# a34g43x register map
Vendor: ABOV Semiconductor Co., Ltd.; File version: 1.0
CPU: CM4 r0p1, little endian, MPU, FPU, VTOR, 4 interrupt priority bits
Registers are 32-bit, read-write, reset 0x0 unless marked. A register's access mark holds for its fields unless they carry their own. Offsets are from the block's base; [hi:lo] are bit positions; 'fields as' and 'values as' point back to an identical list.

## QSPI — Serial Peripheral Interface Bus
Base 0x40020000
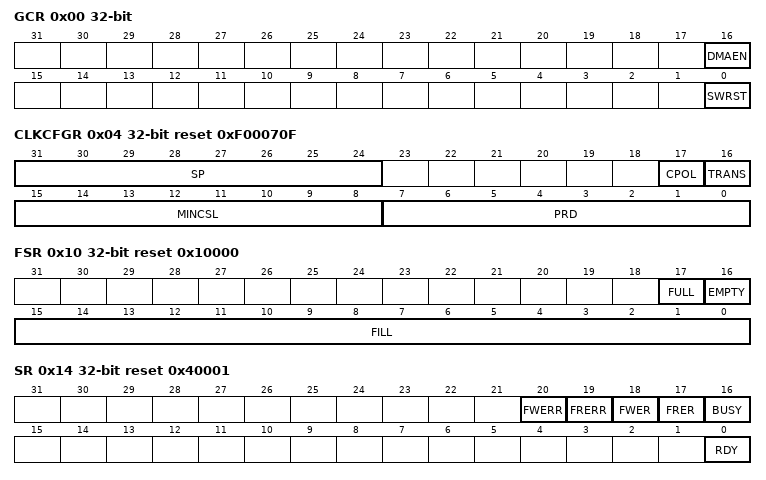
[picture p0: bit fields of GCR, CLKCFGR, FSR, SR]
0x00 GCR — QSPI Global Control Register
  [16] DMAEN — To complete next command using DMA, set this bit to 1.
  [0] SWRST — When set '1', holds most of the internal logic in reset
0x04 CLKCFGR reset 0xF00070F — QSPI Clock Configuration Register
  [31:24] SP — Sets the sampling point of the input
  [17] CPOL — Selects the clock polarity as follows
    0=Start_Low (QSPI clock output starts low and ends low); 1=Start_High (QSPI clock output starts high and ends high)
  [16] TRANS — Select the clock edge on which the output data is changed
  [15:8] MINCSL — Time between CS going active and first clock edge
  [7:0] PRD — The period of the QSPI output clock
0x08 MINCSHR — QSPI Minimum Chip Select High Register
  [7:0] MINCSHR — Required to drive the CS line inactive.
0x10 FSR ro reset 0x10000 — QSPI FIFO Status Register
  [17] FULL — The QSPI FIFO full status bit
    0=NOT_FULL (FIFO is not full); 1=FULL (FIFO is full)
  [16] EMPTY — The QSPI FIFO empty status bit
    0=NOT_EMPTY (FIFO is not empty); 1=EMPTY (FIFO is empty)
  [15:0] FILL — Current FIFO fill level
0x14 SR reset 0x40001 — QSPI Status Register
  [20] FWERR — Erroneous (unexpected) FIFO write detected flag.
  [19] FRERR — Erroneous (unexpected) FIFO read detected.
  [18] FWER ro — Write FIFO indicate status bit.
  [17] FRER ro — Read FIFO indicate status bit.
  [16] BUSY ro — QSPI busy status bit
  [0] RDY ro — QSPI idle status bit.
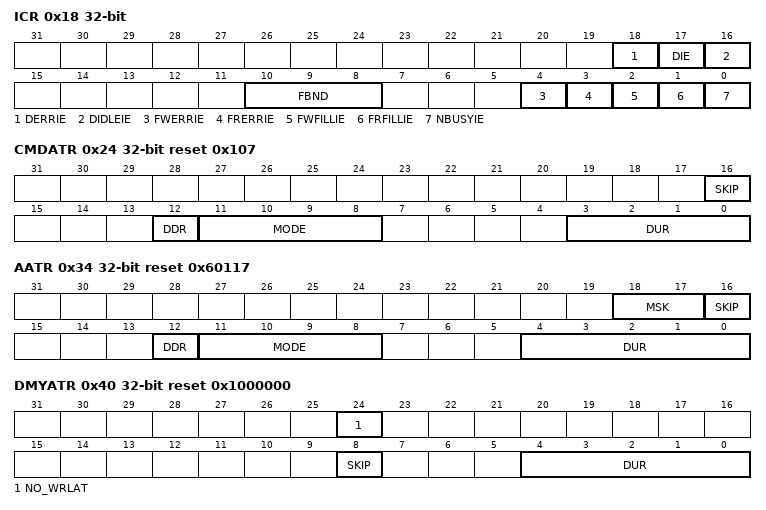
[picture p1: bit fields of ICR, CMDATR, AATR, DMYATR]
0x18 ICR — QSPI Interrupt Control Register
  [18] DERRIE — DMA error interrupt bit.
  [17] DIE — DMA interrupt bit.
  [16] DIDLEIE — DMA idle interrupt bit.
  [10:8] FBND — FIFO boundary
  [4] FWERRIE — Write FIFO error interrupt bit.
  [3] FRERRIE — Read FIFO error interrupt bit.
  [2] FWFILLIE — Write FIFO fill interrupt bit.
  [1] FRFILLIE — Read FIFO fill interrupt bit.
  [0] NBUSYIE — Not busy interrupt bit.
0x20 CMDR — QSPI Command Register
  [15:0] CMD — For commands less than 16 bits wide, align command's most significant bit to bit [15]
0x24 CMDATR reset 0x107 — QSPI Command Atrributes Register
  [16] SKIP — This bit selects whether the command phase is to be skipped or not on the next QSPI transaction and is encoded as follows
  [12] DDR — This bit selects whether the command phase is executed in DDR mode (using both edges of the output clock)
  [11:8] MODE — This field selects the number of lines to use for the command output
    1=Single (x1, 1-bits); 2=Dual (x2, 2-bits); 4=Quad (x4, 4-bits)
  [3:0] DUR — This field must reflect the length of the command phase of the QSPI transaction in QSPI clock cycles minus 1
0x30 AR — QSPI Address Register
  [31:0] ADDR — This field holds the value of the address output on the address phase of the QSPI transaction
0x34 AATR reset 0x60117 — QSPI Address Atrributes Register
  [18:17] MSK — Always '3'.
  [16] SKIP — This bit selects whether the address phase is to be skipped or not on the next QSPI transaction
  [12] DDR — This bit selects whether the address phase is executed in DDR mode (using both edges of the output clock)
  [11:8] MODE — This field selects the number of lines to use for the address output
    values as CMDATR.MODE
  [4:0] DUR — This field must reflect the length of the address phase of the QSPI transaction in QSPI clock cycles minus 1
0x38 CSR reset 0x1 — QSPI Chip Select Register
  [0] CS — Chip Select line.
0x40 DMYATR reset 0x1000000 — QSPI Dummy Attributes Register
  [24] NO_WRLAT — Always '1'.
  [8] SKIP — This bit selects whether the dummy phase is to be skipped or not on the next QSPI transaction
  [4:0] DUR — This field reflects the length of the dummy phase of the SPI transaction in QSPI clock cycles minus 1
0x44 XIPHOTR — QSPI XIP Hold Off Time Register
  [31:0] TIME — when the command is executed with bit [31]='1' in the QSPI Command Attributes Register.
0x48 XIPHOSR — QSPI XIP Hold Off Select Register
  [0] EN — This register gives the XIP windows for which the XIP hold off should be applied
0x4C XIPHOCR — QSPI XIP Hold Off Control Register
  [0] EN — Hold off in XIP enable bit.
0x50 DSZR — QSPI Data Size Register
  [31:0] SIZE — Number of data bits to transmit or receive, minus 1.
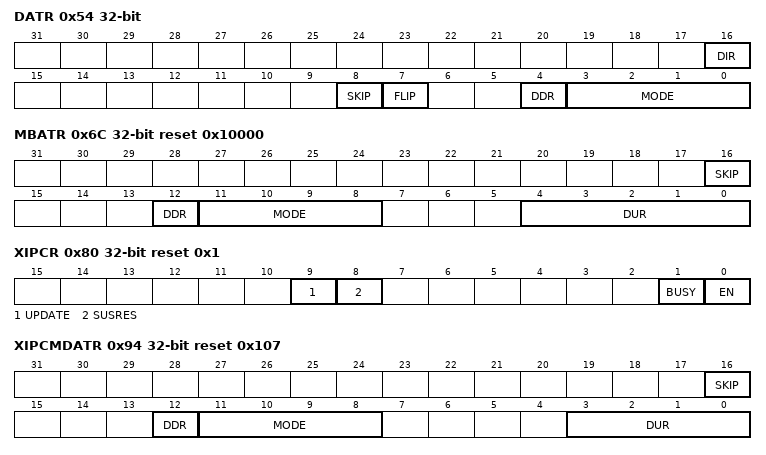
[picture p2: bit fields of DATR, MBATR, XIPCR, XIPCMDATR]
0x54 DATR — QSPI Data Attributes Register
  [16] DIR — Data direction select
  [8] SKIP — This bit selects whether the data phase is to be skipped or not on the next QSPI transaction
  [7] FLIP — Byte order select
  [4] DDR — This bit selects whether the data phase is executed in DDR mode (using both edges of the clock)
  [3:0] MODE — This field selects the number of lines to use for the data output
    values as CMDATR.MODE
0x58 TDR wo — QSPI Transmit Data Register
  [31:0] TDR — Window into the QSPI custom command data FIFO. Writing this register pushes one 32-bit word into the QSPI custom command data FIFO.
0x5C RDR ro — QSPI Receive Data Register
  [31:0] RDR — Window into the SPI custom command data FIFO. Reading this register pops one 32-bit word from the QSPI custom command data FIFO.
0x68 MBR — QSPI Mode Bits Register
  [31:0] MODE — QSPI Mode bits to use for the mode phase of the QSPI transaction
0x6C MBATR reset 0x10000 — QSPI Mode Bits Attributes Register
  [16] SKIP — This bit selects whether the mode phase is to be skipped or not on the next
  [12] DDR — This bit selects whether the mode phase is executed in DDR mode (using both edges of the clock)
  [11:8] MODE — This field selects the number of lines to use for the mode output
    values as CMDATR.MODE
  [4:0] DUR — This field must reflect the length of the mode phase of the QSPI transaction in QSPI clock cycles minus 1
0x80 XIPCR reset 0x1 — XIP Control Register
  [9] UPDATE — If this bit is set to 1, the attributes specified in the New XIP * registers are applied
  [8] SUSRES — Set to 1 to enable suspend/resume support. Setting this bit is only applied when bit [9] is also set to 1
  [1] BUSY — XIP operation state
  [0] EN — Enable the XIP window.
0x84 XIPACCBNDR reset 0x1F — QSPI XIP Access Boundary Register
  [4:0] BND — Access boundary for XIP accesses
0x88 XIPSZR reset 0x1FFFFF — QSPI XIP Size Register
  [27:0] SIZE — This register gives the size of this XIP window
0x8C XIPWINAR — QSPI XIP Window Address Register
  [27:0] ADDR — For window 0: This register is hard wired to '0'
0x90 XIPCMDR reset 0xB00 — QSPI XIP Command Register
  [15:0] RCMD — QSPI command to use for XIP reads.
0x94 XIPCMDATR reset 0x107 — QSPI XIP Command Attributes Register
  [16] SKIP — This bit selects whether the command phase is to be skipped or not for XIP-based QSPI transactions
  [12] DDR — This bit selects whether the command phase is executed in DDR mode (using both edges of the output clock)
  [11:8] MODE — This field selects the number of lines to use for XIP command output
    values as CMDATR.MODE
  [3:0] DUR — This field must reflect the length of the command phase of the XIP read in QSPI clock cycles minus 1
0xA0 XIPBAR — QSPI XIP Base Address Register
  [31:0] ADDR — This register selects the memory address to which the controller maps address 0 on the XIP slave interface.
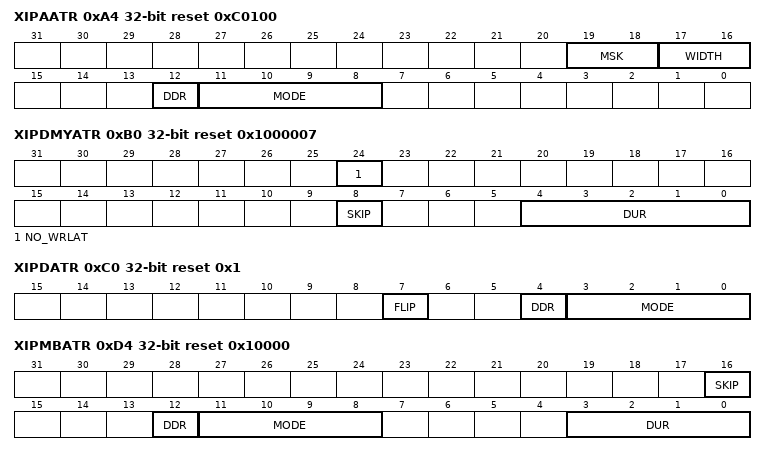
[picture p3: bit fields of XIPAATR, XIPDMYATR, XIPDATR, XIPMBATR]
0xA4 XIPAATR reset 0xC0100 — QSPI XIP Address Attributes Register
  [19:18] MSK — Always '3'.
  [17:16] WIDTH — Select address length used for XIP reads
  [12] DDR — Address DDR mode after update
  [11:8] MODE — This field selects the number of lines to use for the address output
    values as CMDATR.MODE
0xA8 XIPCSR reset 0x1 — QSPI XIP Chip Select Register
  [0] CS — The chip select line to use for XIP mode reads
0xB0 XIPDMYATR reset 0x1000007 — QSPI XIP Dummy Attributes Register
  [24] NO_WRLAT — Always '1'.
  [8] SKIP — This bit selects whether the dummy phase is to be skipped or not on XIP reads
  [4:0] DUR — This field reflects the length of the dummy phase of the XIP read in QSPI clock cycles minus 1.
0xC0 XIPDATR reset 0x1 — QSPI XIP Data Attributes Register
  [7] FLIP — Byte order select
  [4] DDR — This bit selects whether the data phase is executed in DDR mode (using both edges of the clock)
  [3:0] MODE — This field selects the number of lines to use for the data output
    values as CMDATR.MODE
0xD0 XIPMBR — QSPI XIP Mode Bits Register
  [31:0] MODE — QSPI Mode bits to use for the mode phase of XIP reads
0xD4 XIPMBATR reset 0x10000 — QSPI XIP Mode Bits Attributes Register
  [16] SKIP — This bit selects whether the mode phase is to be skipped or not XIP reads
  [12] DDR — This bit selects whether the mode phase is executed in DDR mode (using both edges of the clock)
  [11:8] MODE — This field selects the number of lines to use for the mode output
    values as CMDATR.MODE
  [3:0] DUR — This field must reflect the length of the mode phase of XIP reads QSPI clock cycles minus 1
0xE0 DMASTAR — QSPI DMA Start Address Register
  [29:0] ADDR — Set address for the first DMA descriptor.
0xE4 DMAFBLSR reset 0xF00 — QSPI DMA Master Fixed Burst Length Select Register
  [1:0] LEN — Select AHB Master interfaces preferred incremental burst behavior
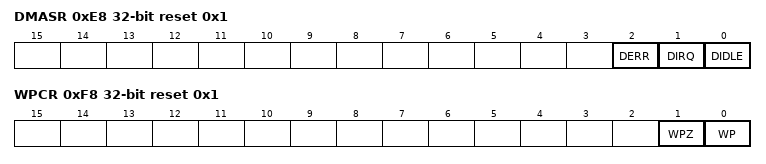
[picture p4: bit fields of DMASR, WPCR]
0xE8 DMASR reset 0x1 — QSPI DMA Status Register
  [2] DERR — When set, it indicates that DMA completed with an error
  [1] DIRQ — When set, it indicates DMA successfully transferred one or more buffer descriptors with IRQ bit set
  [0] DIDLE ro — Indicates DMA is available to process new requests
0xEC DMABDCNTR ro — QSPI DMA Buffer Descriptor Count Register
  [31:0] CNT — Indicates how many DMA buffer descriptors were successfully transferred during last DMA transfer
0xF8 WPCR reset 0x1 — QSPI Write Protect Control Register
  [1] WPZ — State of bit 2 during idle (CS inactive)
  [0] WP — Value to drive on the data bit 2 during idle (CS inactive)
0xFC HTR reset 0x7 — QSPI Hold Time Register
  [7:0] TIME — Specifies the hold time of the output value for the phase preceeding the dummy phase during QSPI transactions
